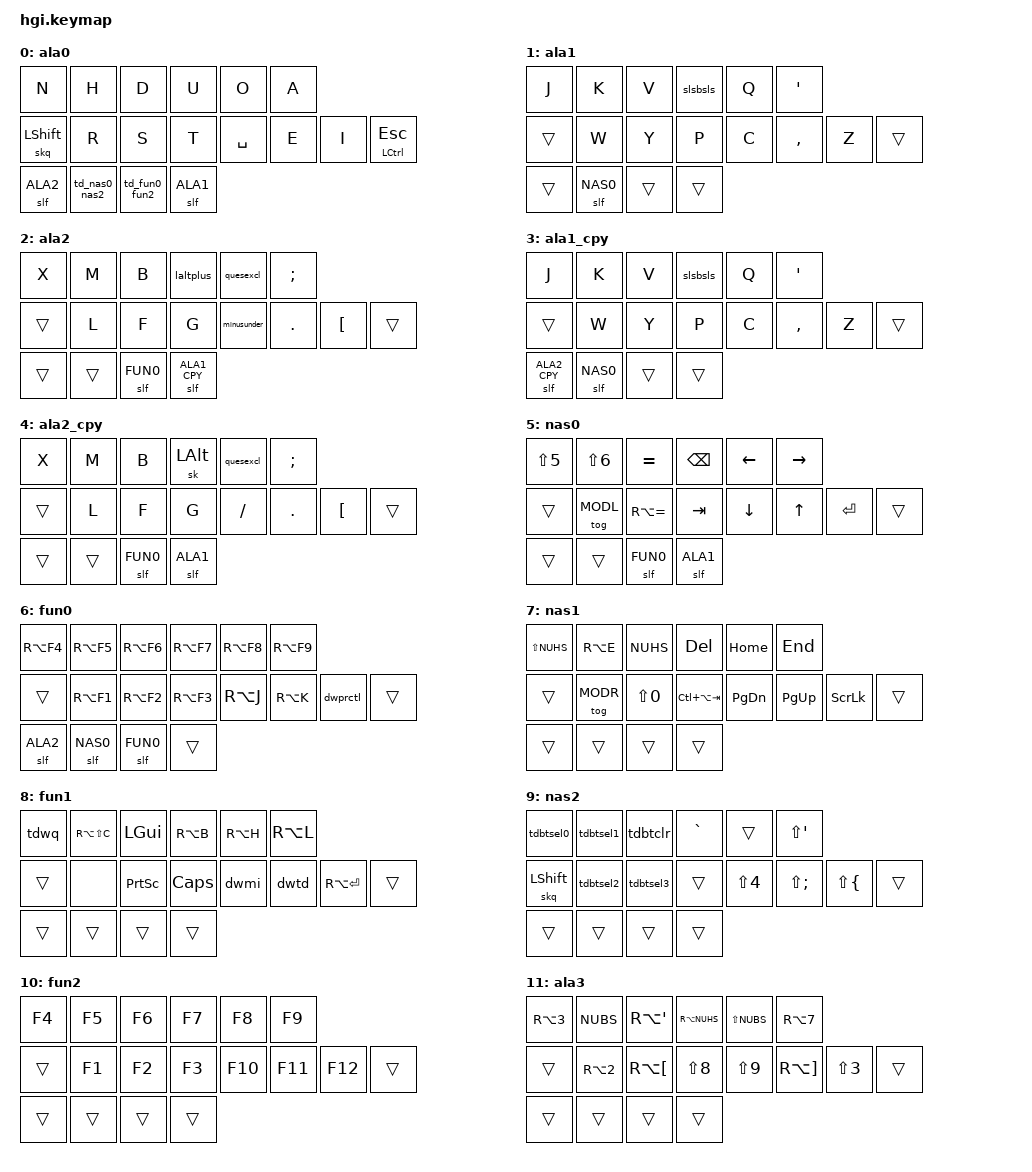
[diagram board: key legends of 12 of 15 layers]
/*
* Copyright (c) 2020 The ZMK Contributors
*
* SPDX-License-Identifier: MIT
*/

#include <behaviors.dtsi>
#include <dt-bindings/zmk/keys.h>
#include <dt-bindings/zmk/bt.h>

&mt {
  tapping-term-ms = <500>;
};
&sk {
  release-after-ms = <2000>;
  quick-release;
};

/* Layers */
#define ALA0        0
#define ALA1        1
#define ALA2        2
#define ALA1_CPY    3
#define ALA2_CPY    4
#define NAS0        5
#define FUN0        6
#define NAS1        7
#define FUN1        8
#define NAS2        9
#define FUN2       10
#define ALA3       11
#define ALA4       12
#define MODL       13
#define MODR       14

/ {

  pair_inhibitors {
    compatible = "zmk,pair-inhibitor";
    pair_inhibitor_L1_H1 {
      key-positions-pair = <1 2>;
      timeout-ms = <1000>;
    };
  };

  delay {
    compatible = "zmk,delay";
    configuration {
      timeout-ms = <40>;
      layer-key-positions = <6 13 14 15 16 17>;
    };
  }; 

  behaviors {
    skq: sticky_key_quick_release {
      compatible = "zmk,behavior-sticky-key";
      #binding-cells = <1>;
      bindings = <&kp>;
      release-after-ms = <50>; // keep that low, e.g. with 100ms, it is possible to to quickly press RCTL (involving LSFT, and key.pos.16) and then select other desktop (also involving key.pos.16, but NOT LSFT) but LSFT then is still active, i.e. effectively MOVING current app to other desktop
      quick-release;
      ignore-modifiers;
    };
    
    slf: sticky_layer_fast_release {
      compatible = "zmk,behavior-sticky-key";
      #binding-cells = <1>;
      release-after-ms = <100>;
      bindings = <&mo>;
      ignore-modifiers;
    };
    sls: sticky_layer_slow_release {
      compatible = "zmk,behavior-sticky-key";
      #binding-cells = <1>;
      release-after-ms = <1000>;
      bindings = <&mo>;
      ignore-modifiers;
    };

    td: tapdance {
      compatible = "zmk,behavior-hold-tap";
      #binding-cells = <2>;
      tapping-term-ms = <190>;
      quick-tap-ms = <250>;
      flavor = "tap-preferred";
      bindings = <&kp>, <&kp>;
    };

    quesexcl: quesexcl {
      compatible = "zmk,behavior-mod-morph";
      #binding-cells = <0>;
      bindings = <&kp LS(MINUS)>, <&kp LS(RBKT)>;
      mods = <(MOD_LSFT)>;
    };
    
    slsbsls: slsbsls {
      compatible = "zmk,behavior-mod-morph";
      #binding-cells = <0>;
      bindings = <&kp LS(N7)>, <&kp RA(NUBS)>;
      mods = <(MOD_LSFT)>;
    };

    dwmi: dwm_m_i {
      compatible = "zmk,behavior-mod-morph";
      #binding-cells = <0>;
      bindings = <&kp RA(M)>, <&kp RA(I)>;
      mods = <(MOD_LSFT)>;
    };
    
    dwtd: dwm_t_d {
      compatible = "zmk,behavior-mod-morph";
      #binding-cells = <0>;
      bindings = <&kp RA(T)>, <&kp RA(D)>;
      mods = <(MOD_LSFT)>;
    };
    
    dwprctl: dwm_p_rctl {
      compatible = "zmk,behavior-mod-morph";
      #binding-cells = <0>;
      bindings = <&kp RA(P)>, <&kp RCTL>;
      mods = <(MOD_LSFT)>;
    };
    
    n7bspc: n7_bspc  {
      compatible = "zmk,behavior-mod-morph";
      #binding-cells = <0>;
      bindings = <&kp N7>, <&kp BSPC>;
      mods = <(MOD_LSFT)>;
    };

    n9deg: n9_deg  {
      compatible = "zmk,behavior-mod-morph";
      #binding-cells = <0>;
      bindings = <&kp N9>, <&kp LS(GRAVE)>;
      mods = <(MOD_LSFT)>;
    };

    aposgrave: apos_grave  {
      compatible = "zmk,behavior-mod-morph";
      #binding-cells = <0>;
      bindings = <&kp MINUS>, <&kp LS(EQUAL)>;
      mods = <(MOD_LSFT)>;
    };

    laltplus: lalt_plus {
      compatible = "zmk,behavior-mod-morph";
      #binding-cells = <0>;
      bindings = <&sk LALT>, <&kp LS(N1)>;
      mods = <(MOD_LSFT)>;
    };

    minusunder: minus_under  {
      compatible = "zmk,behavior-mod-morph";
      #binding-cells = <0>;
      bindings = <&kp SLASH>, <&kp LS(SLASH)>;
      mods = <(MOD_LSFT)>;
    };
    
    tdwq: tap_dance_wq {
      compatible = "zmk,behavior-tap-dance";
      #binding-cells = <0>;
      tapping-term-ms = <200>;
      bindings = <&none>, <&kp RA(LS(Q))>;
    };

    tdbtsel0: tap_dance_bt_sel0 {
      compatible = "zmk,behavior-tap-dance";
      #binding-cells = <0>;
      tapping-term-ms = <200>;
      bindings = <&none>, <&bt BT_SEL 0>;
    };

    tdbtsel1: tap_dance_bt_sel1 {
      compatible = "zmk,behavior-tap-dance";
      #binding-cells = <0>;
      tapping-term-ms = <200>;
      bindings = <&none>, <&bt BT_SEL 1>;
    };

    tdbtsel2: tap_dance_bt_sel2 {
      compatible = "zmk,behavior-tap-dance";
      #binding-cells = <0>;
      tapping-term-ms = <200>;
      bindings = <&none>, <&bt BT_SEL 2>;
    };

    tdbtsel3: tap_dance_bt_sel3 {
      compatible = "zmk,behavior-tap-dance";
      #binding-cells = <0>;
      tapping-term-ms = <200>;
      bindings = <&none>, <&bt BT_SEL 3>;
    };

    tdbtclr: tap_dance_bt_clr {
      compatible = "zmk,behavior-tap-dance";
      #binding-cells = <0>;
      tapping-term-ms = <200>;
      bindings = <&none>, <&bt BT_CLR>;
    };

    td_nas0_nas2: tap_dance_nas0_nas2 {
      compatible = "zmk,behavior-tap-dance";
      #binding-cells = <0>;
      tapping-term-ms = <300>;
      bindings = <&slf NAS0>, <&slf NAS0>, <&sls NAS2>;
    };
    td_fun0_fun2: tap_dance_fun0_fun2 {
      compatible = "zmk,behavior-tap-dance";
      #binding-cells = <0>;
      tapping-term-ms = <300>;
      bindings = <&slf FUN0>, <&sls FUN2>;
    };
    
	  ala1macro: ala1_macro {
		  compatible = "zmk,behavior-macro";
		  #binding-cells = <0>;
		  bindings = < &slf  ALA1>;
	  };

	  ala2macro: ala2_macro {
		  compatible = "zmk,behavior-macro";
		  #binding-cells = <0>;
		  bindings = < &slf  ALA2>;
	  };
  };

  
  conditional_layers {
    compatible = "zmk,conditional-layers";

    // Defining the directed activation of the conditional layers
    // ---------------------------------------------------------- 
   
    // ALA3 and ALA4

    to_ala3 {
      if-layers = <NAS0 FUN0>;
      then-layer = <ALA3>;
    };

    to_ala4a {
      if-layers = <ALA2 ALA1>;
      then-layer = <ALA4>;
    };

    to_ala4b {
      if-layers = <ALA2 ALA1_CPY>;
      then-layer = <ALA4>;
    };

    to_ala4c {
      if-layers = <ALA2_CPY ALA1_CPY>;
      then-layer = <ALA4>;
    };

    to_ala4d {
      if-layers = <ALA2_CPY ALA1>;
      then-layer = <ALA4>;
    };

    // Defining the UN-directed activation of the conditional layers
    // ------------------------------------------------------------- 

    to_nas1 {
      if-layers = <ALA1 NAS0>;
      then-layer = <NAS1>;
    };

    to_fun1 {
      if-layers = <ALA2 FUN0>;
      then-layer = <FUN1>;
    };

  };


  /*
   * Read the following map's positions horizontally, from left to right:
   * finger tip-L: 0..7
   * finger tip-H: 8..15
   * finger interphalangeal-L : 16..23
   * finger interphalangeal-L : 24..31
   * thumb  tip-L: 32, 33
   * thumb  tip-H: 34, 35
   * thumb  interphalangeal-L : 36, 37
   * thumb  interphalangeal-L : 38, 39
   * 
   *        0    4    8    12                     32    28    24    20      
   *         1    5    9    13                     33    29    25    21
   *
   *        2    6    10    14                     34    30    26    22
   *         3    7    11    15                     35    31    27    23
   *
   *                                 16    36
   *                                  17    37
   *
   *                                 18    38
   *                                  19    39
   */ 

  keymap {
    compatible = "zmk,keymap";
    
    ala0 {
      bindings = <
      &kp N               &kp H               &kp D               &kp U               &kp O               &kp A
      &skq LSHIFT         &kp R               &kp S               &kp T               &kp SPACE           &kp E               &kp I               &mt LCTRL ESC
      &slf ALA2           &td_nas0_nas2       &td_fun0_fun2       &slf ALA1
      >;
    };

    ala1 {
      bindings = <
      &kp J               &kp K               &kp V               &slsbsls            &kp Q               &kp SQT  
      &trans              &kp W               &kp Y               &kp P               &kp C               &kp COMMA           &kp Z               &trans
      &trans              &slf NAS0           &trans              &trans
      >;
    };

    ala2 {
      bindings = <
      &kp X               &kp M               &kp B               &laltplus           &quesexcl           &kp SEMI 
      &trans              &kp L               &kp F               &kp G               &minusunder         &kp DOT             &kp LBKT               &trans
      &trans              &trans              &slf FUN0           &slf ALA1_CPY
      >;
    };

    ala1_cpy {
      bindings = <
      &kp J               &kp K               &kp V               &slsbsls            &kp Q               &kp SQT  
      &trans              &kp W               &kp Y               &kp P               &kp C               &kp COMMA           &kp Z               &trans
      &slf ALA2_CPY       &slf NAS0           &trans              &trans
      >;
    };

    ala2_cpy {
      bindings = <
      &kp X               &kp M               &kp B               &sk LALT            &quesexcl           &kp SEMI 
      &trans              &kp L               &kp F               &kp G               &kp SLASH           &kp DOT             &kp LBKT               &trans
      &trans              &trans              &slf FUN0           &slf ALA1
      >;
    };

    nas0 {
      bindings = <
      &kp LS(N5)          &kp LS(N6)          &kp EQUAL           &kp BSPC            &kp LEFT            &kp RIGHT
      &trans              &tog MODL           &kp RA(EQUAL)       &kp TAB             &kp DOWN            &kp UP              &kp ENTER           &trans
      &trans              &trans              &slf FUN0           &slf ALA1
      >; 
    };

    fun0 {
      bindings = <
      &kp RA(F4)          &kp RA(F5)          &kp RA(F6)          &kp RA(F7)          &kp RA(F8)          &kp RA(F9)           
      &trans              &kp RA(F1)          &kp RA(F2)          &kp RA(F3)          &kp RA(J)           &kp RA(K)           &dwprctl            &trans
      &slf ALA2           &slf NAS0           &slf FUN0           &trans
      >;
    };
    
    nas1 {
      bindings = <
      &kp LS(NUHS)        &kp RA(E)           &kp NUHS            &kp DEL             &kp HOME            &kp END
      &trans              &tog MODR           &kp LS(N0)          &kp LC(LA(TAB))     &kp PG_DN           &kp PG_UP           &kp SCROLLLOCK      &trans
      &trans              &trans              &trans              &trans              
      >;
    };

    fun1 {
      bindings = <
      &tdwq               &kp RA(LS(C))       &kp LGUI            &kp RA(B)           &kp RA(H)           &kp RA(L)         
      &trans              &none               &kp PSCRN           &kp CAPS              &dwmi               &dwtd               &kp RA(ENTER)       &trans
      &trans              &trans              &trans              &trans              
      >;
    };

    nas2 {
      bindings = <
      &tdbtsel0           &tdbtsel1           &tdbtclr            &kp GRAVE           &trans              &kp LS(SQT)   
      &skq LSHIFT         &tdbtsel2           &tdbtsel3           &trans              &kp LS(N4)          &kp LS(SEMI)        &kp LS(LBRC)        &trans
      &trans              &trans              &trans              &trans              
      >;
    };
    
    fun2 {
      bindings = <
      &kp F4              &kp F5              &kp F6              &kp F7              &kp F8              &kp F9               
      &trans              &kp F1              &kp F2              &kp F3              &kp F10             &kp F11             &kp F12             &trans
      &trans              &trans              &trans              &trans              
      >;
    };

    ala3 {
      bindings = <
      &kp RA(N3)          &kp NUBS            &kp RA(SQT)         &kp RA(NUHS)        &kp LS(NUBS)        &kp RA(N7) 
      &trans              &kp RA(N2)          &kp RA(LBKT)        &kp LS(N8)          &kp LS(N9)          &kp RA(RBKT)        &kp LS(N3)           &trans
      &trans              &trans              &trans              &trans
      >;
    };

    ala4 {
      bindings = <
      &kp N4              &kp N5              &kp N6              &n7bspc             &kp N8              &n9deg
      &trans              &kp N1              &kp N2              &kp N3              &kp N0              &aposgrave          &kp LS(N2)          &trans
      &trans              &trans              &trans              &trans
      >;
    };

    modl {
      bindings = <
      &kp RALT            &trans              &kp LGUI            &trans              &trans              &trans            
      &tog MODL           &kp LALT            &kp LSFT            &kp LCTL            &trans              &trans              &trans              &trans
      &trans              &trans              &trans              &trans              
      >;
    };

    modr {
      bindings = <
      &trans              &trans              &trans              &kp RGUI            &trans              &kp RALT          
      &trans              &trans              &trans              &trans              &kp RCTL            &kp RSFT            &kp LALT            &tog MODR
      &trans              &trans              &trans              &trans              
      >;
    };
  };
};
